# PIC16F1768 register map
Vendor: Microchip
Registers are 8-bit, read-write, reset 0x0 unless marked. A register's access mark holds for its fields unless they carry their own. Addresses are absolute, and some are shared; only a register's first bit layout is shown; [hi:lo] are bit positions; {n}, {i} and the like mark numbered series.

## SFR
0x00 INDF0 reset not defined — (power-on value xxxxxxxx)
0x01 INDF1 reset not defined — (power-on value xxxxxxxx)
0x02 PCL
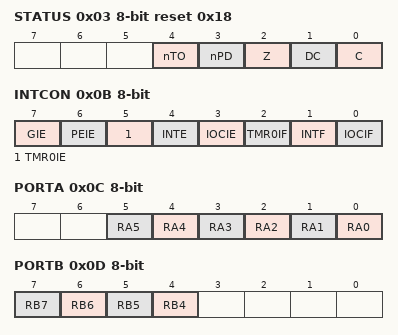
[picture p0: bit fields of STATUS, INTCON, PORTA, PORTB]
0x03 STATUS reset 0x18
  [4] nTO ro, [3] nPD ro, [2] Z, [1] DC, [0] C
0x04 FSR0L
0x05 FSR0H
0x06 FSR1L
0x07 FSR1H
0x08 BSR
  [4:0] BSR
0x09 WREG
  [7:0] WREG0
0x0A PCLATH
  [6:0] PCLATH
0x0B INTCON reset not defined — (power-on value 0000000x)
  [7] GIE, [6] PEIE, [5] TMR0IE, [4] INTE, [3] IOCIE, [2] TMR0IF, [1] INTF, [0] IOCIF ro
0x0C PORTA reset not defined — (power-on value --xxxxxx)
  [n] RA{n} (n=0..5)
0x0D PORTB reset not defined — (power-on value xxxx----)
  [n] RB{n} (n=4..7)
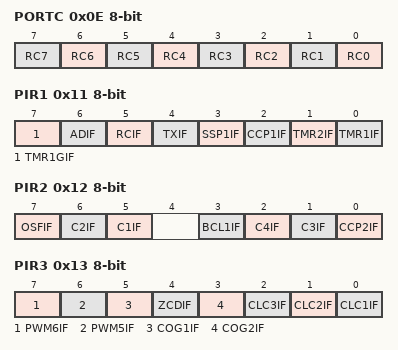
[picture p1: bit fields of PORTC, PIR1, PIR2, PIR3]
0x0E PORTC reset not defined — (power-on value xxxxxxxx)
  [n] RC{n} (n=0..7)
0x11 PIR1
  [7] TMR1GIF — Timer1 Gate Interrupt Flag bit
  [6] ADIF — A/D Converter Interrupt Flag bit
  [5] RCIF — EUSART Receive Interrupt Enable bit
  [4] TXIF — EUSART Transmit Interrupt Enable bit
  [3] SSP1IF — Synchronous Serial Port (MSSP) Interrupt Flag bit
  [2] CCP1IF
  [1] TMR2IF — TMR2 to PR2 Match Interrupt Flag bit
  [0] TMR1IF — TMR1 Overflow Interrupt Flag bit
0x12 PIR2
  [7] OSFIF — Oscillator Fail Interrupt Enable bit
  [6] C2IF — Numerically Controlled Oscillator Flag bit
  [5] C1IF — Numerically Controlled Oscillator Flag bit
  [3] BCL1IF — MSSP Bus Collision Interrupt Flag bit
  [2] C4IF — Numerically Controlled Oscillator Flag bit
  [1] C3IF
  [0] CCP2IF
0x13 PIR3
  [7] PWM6IF
  [6] PWM5IF
  [5] COG1IF
  [4] ZCDIF
  [3] COG2IF
  [2] CLC3IF — Configurable Logic Block Interrupt Flag
  [1] CLC2IF — Configurable Logic Block Interrupt Flag
  [0] CLC1IF — Configurable Logic Block Interrupt Flag
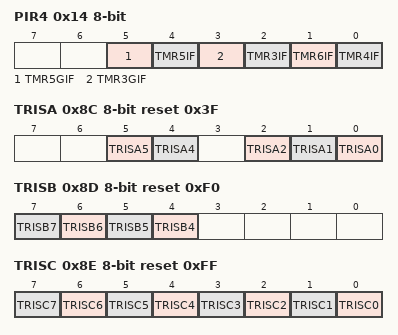
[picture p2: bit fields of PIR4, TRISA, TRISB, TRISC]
0x14 PIR4
  [5] TMR5GIF, [4] TMR5IF, [3] TMR3GIF, [2] TMR3IF, [1] TMR6IF, [0] TMR4IF
0x15 TMR0
0x8C TRISA reset 0x3F — PORTA Data Direction Control Register
  [5] TRISA5, [4] TRISA4, [2] TRISA2, [1] TRISA1, [0] TRISA0
0x8D TRISB reset 0xF0
  [n] TRISB{n} (n=4..7)
0x8E TRISC reset 0xFF — PORTC Data Direction Control Register
  [n] TRISC{n} (n=0..7)
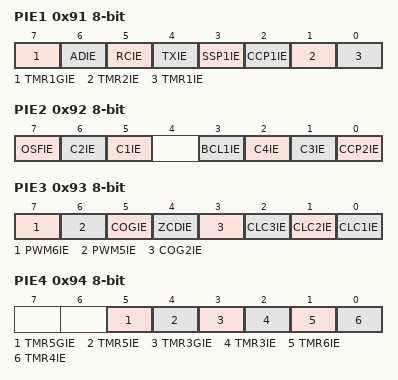
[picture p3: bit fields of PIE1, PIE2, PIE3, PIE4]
0x91 PIE1 — Peripheral Interrupt Enable Register 1
  [7] TMR1GIE — Timer1 Gate Interrupt Enable bit
  [6] ADIE — A/D Converter Interrupt Enable bit
  [5] RCIE
  [4] TXIE
  [3] SSP1IE
  [2] CCP1IE
  [1] TMR2IE — TMR2 to PR2 Match Interrupt Enable bit
  [0] TMR1IE — TMR1 Overflow Interrupt Enable bit
0x92 PIE2 — Peripheral Interrupt Enable Register 2
  [7] OSFIE, [6] C2IE, [5] C1IE, [3] BCL1IE, [2] C4IE, [1] C3IE, [0] CCP2IE
0x93 PIE3 — Peripheral Interrupt Enable Register 3
  [7] PWM6IE, [6] PWM5IE, [5] COGIE, [4] ZCDIE, [3] COG2IE, [2] CLC3IE, [1] CLC2IE, [0] CLC1IE
0x94 PIE4
  [5] TMR5GIE, [4] TMR5IE, [3] TMR3GIE, [2] TMR3IE, [1] TMR6IE, [0] TMR4IE
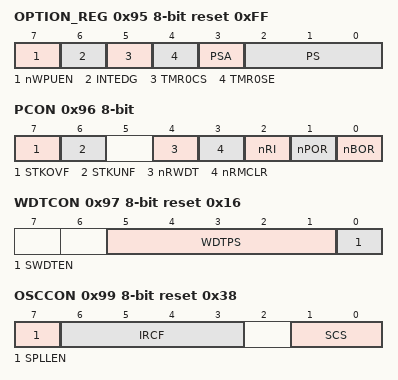
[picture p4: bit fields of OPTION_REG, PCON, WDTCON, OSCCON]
0x95 OPTION_REG reset 0xFF — Option Register
  [7] nWPUEN — Weak Pull-up Enable bit
  [6] INTEDG — Interrupt Edge Select bit
  [5] TMR0CS
  [4] TMR0SE — TMR0 Source Edge Select bit
  [3] PSA — Prescaler Active bit
  [2:0] PS
0x96 PCON reset not defined — Power Control Register (power-on value 00-111qq)
  [7] STKOVF — Stack Overflow Flag bit
  [6] STKUNF — Stack Underflow Flag bit
  [4] nRWDT
  [3] nRMCLR — MCLR Reset Flag bit
  [2] nRI — RESET Instruction Flag bit
  [1] nPOR — Power-on Reset Status bit
  [0] nBOR — Brown-out Reset Status bit
0x97 WDTCON reset 0x16 — Watchdog Timer Control Register
  [5:1] WDTPS
  [0] SWDTEN — Software Enable/Disable for Watch Dog Timer bit
0x98 OSCTUNE
  [5:0] TUN
0x99 OSCCON reset 0x38 — Oscillator Control Register
  [7] SPLLEN, [6:3] IRCF, [1:0] SCS
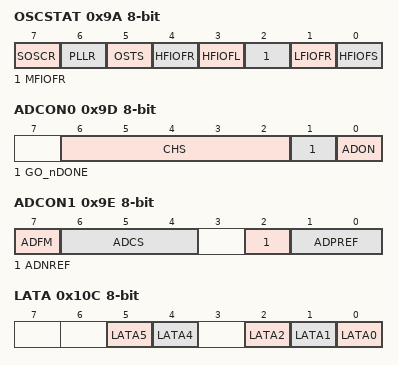
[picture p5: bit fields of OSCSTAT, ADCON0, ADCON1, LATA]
0x9A OSCSTAT ro reset not defined — Oscillator Status Register (power-on value 0qq00q0q)
  [7] SOSCR
  [6] PLLR
  [5] OSTS — Oscillator Start-up Time-out Status bit
  [4] HFIOFR
  [3] HFIOFL
  [2] MFIOFR
  [1] LFIOFR — Low Freqency Internal Oscillator Ready bit
  [0] HFIOFS — Low Freqency Internal Oscillator Ready bit
0x9B ADRESL reset not defined — A/D Result Register LSB (power-on value xxxxxxxx)
0x9C ADRESH reset not defined — A/D Result Register MSB (power-on value xxxxxxxx)
0x9D ADCON0 — Analog-to-Digital Control Register 0
  [6:2] CHS
  [1] GO_nDONE — A/D Conversion Status bit
  [0] ADON — A/D Module Enable bit
0x9E ADCON1 — Analog-to-Digital Control Register 1
  [7] ADFM — A/D Result Format Select bit
  [6:4] ADCS
  [2] ADNREF
  [1:0] ADPREF
0x9F ADCON2 — Analog-to-Digital Control Register 2
  [7:3] TRIGSEL
0x10C LATA reset not defined — (power-on value --xx-xxx)
  [5] LATA5, [4] LATA4, [2] LATA2, [1] LATA1, [0] LATA0
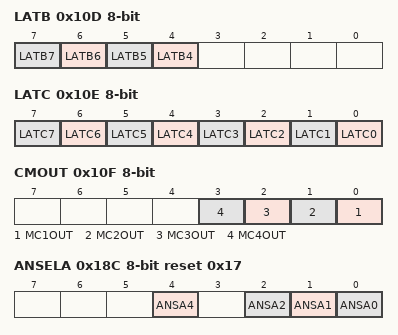
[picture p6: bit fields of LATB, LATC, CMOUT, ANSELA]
0x10D LATB reset not defined — (power-on value xxxx----)
  [n] LATB{n} (n=4..7)
0x10E LATC reset not defined — (power-on value xxxxxxxx)
  [n] LATC{n} (n=0..7)
0x10F CMOUT ro
  [n-1] MC{n}OUT (n=1..4)
0x18C ANSELA reset 0x17
  [4] ANSA4, [2] ANSA2, [1] ANSA1, [0] ANSA0
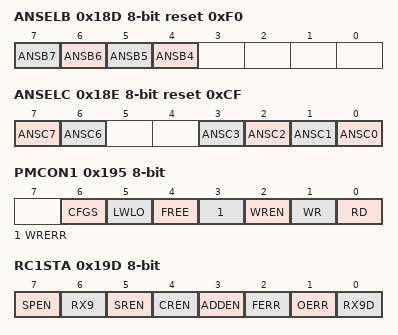
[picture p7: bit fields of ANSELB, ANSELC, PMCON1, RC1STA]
0x18D ANSELB reset 0xF0
  [n] ANSB{n} (n=4..7)
0x18E ANSELC reset 0xCF
  [7] ANSC7, [6] ANSC6, [n] ANSC{n} (n=0..3)
0x191 PMADRL
0x192 PMADRH reset 0x80
  [6:0] PMADRH
0x193 PMDATL reset not defined — (power-on value xxxxxxxx)
0x194 PMDATH reset not defined — (power-on value --xxxxxx)
  [5:0] PMDATH
0x195 PMCON1 reset not defined — (power-on value 1000x000)
  [6] CFGS — FLASH Program / Data EEPROM or Configuration Select bit
  [5] LWLO — Load Write Latches Only bit
  [4] FREE — Program FLASH Erase Enable bit
  [3] WRERR — Sequence Error Flag bit
  [2] WREN — Program/Erase Enable bit
  [1] WR — Write Control bit (can only be set)
  [0] RD — Read Control bit (can only be set)
0x196 PMCON2 wo
0x197 VREGCON reset 0x1
  [1] VREGPM
0x199 RC1REG ro
0x19A TX1REG
0x19B SP1BRGL
0x19C SP1BRGH
0x19D RC1STA
  [7] SPEN, [6] RX9, [5] SREN, [4] CREN, [3] ADDEN, [2] FERR ro, [1] OERR ro, [0] RX9D ro
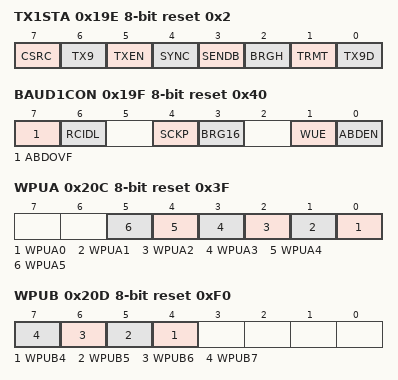
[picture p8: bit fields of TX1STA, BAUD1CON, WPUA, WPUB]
0x19E TX1STA reset 0x2
  [7] CSRC, [6] TX9, [5] TXEN, [4] SYNC, [3] SENDB, [2] BRGH, [1] TRMT ro, [0] TX9D
0x19F BAUD1CON reset 0x40
  [7] ABDOVF ro, [6] RCIDL ro, [4] SCKP, [3] BRG16, [1] WUE, [0] ABDEN
0x20C WPUA reset 0x3F
  [n] WPUA{n} (n=0..5)
0x20D WPUB reset 0xF0
  [n] WPUB{n} (n=4..7)
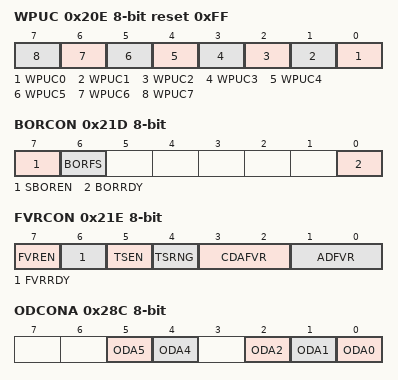
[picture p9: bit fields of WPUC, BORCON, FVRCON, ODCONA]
0x20E WPUC reset 0xFF
  [n] WPUC{n} (n=0..7)
0x21D BORCON reset not defined — (power-on value 10-----q)
  [7] SBOREN, [6] BORFS, [0] BORRDY ro
0x21E FVRCON reset not defined — (power-on value 0q000000)
  [7] FVREN, [6] FVRRDY ro, [5] TSEN, [4] TSRNG, [3:2] CDAFVR, [1:0] ADFVR
0x28C ODCONA
  [5] ODA5, [4] ODA4, [2] ODA2, [1] ODA1, [0] ODA0
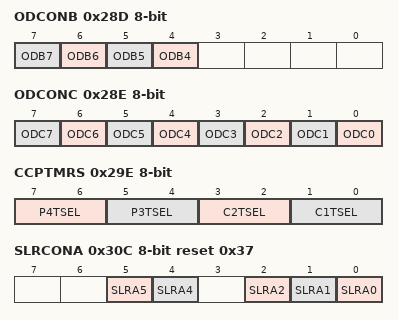
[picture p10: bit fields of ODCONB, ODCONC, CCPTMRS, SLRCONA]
0x28D ODCONB
  [n] ODB{n} (n=4..7)
0x28E ODCONC
  [n] ODC{n} (n=0..7)
0x29E CCPTMRS
  [7:6] P4TSEL, [5:4] P3TSEL, [3:2] C2TSEL, [1:0] C1TSEL
0x30C SLRCONA reset 0x37
  [5] SLRA5, [4] SLRA4, [2] SLRA2, [1] SLRA1, [0] SLRA0
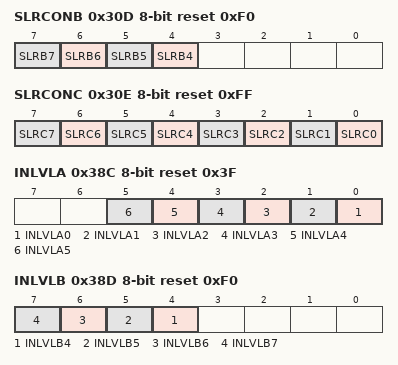
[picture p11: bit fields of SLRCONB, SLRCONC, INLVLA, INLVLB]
0x30D SLRCONB reset 0xF0
  [n] SLRB{n} (n=4..7)
0x30E SLRCONC reset 0xFF
  [n] SLRC{n} (n=0..7)
0x38C INLVLA reset 0x3F
  [n] INLVLA{n} (n=0..5)
0x38D INLVLB reset 0xF0
  [n] INLVLB{n} (n=4..7)
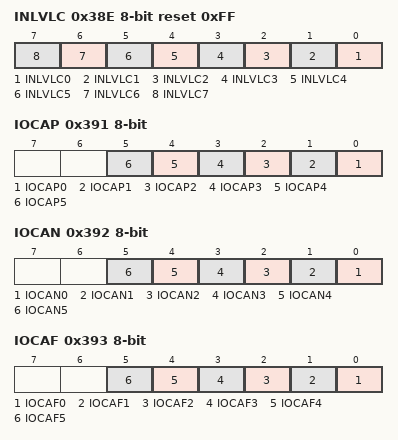
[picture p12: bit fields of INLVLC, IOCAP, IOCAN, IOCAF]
0x38E INLVLC reset 0xFF
  [n] INLVLC{n} (n=0..7)
0x391 IOCAP
  [n] IOCAP{n} (n=0..5)
0x392 IOCAN
  [n] IOCAN{n} (n=0..5)
0x393 IOCAF
  [n] IOCAF{n} (n=0..5)
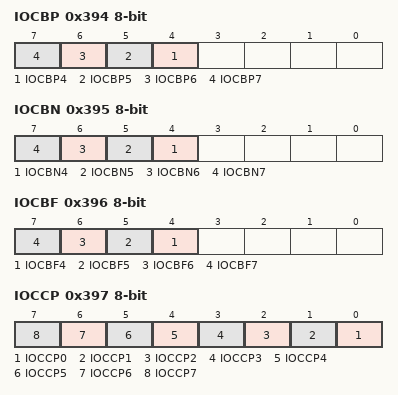
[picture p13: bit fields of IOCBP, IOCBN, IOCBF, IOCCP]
0x394 IOCBP
  [n] IOCBP{n} (n=4..7)
0x395 IOCBN
  [n] IOCBN{n} (n=4..7)
0x396 IOCBF
  [n] IOCBF{n} (n=4..7)
0x397 IOCCP
  [n] IOCCP{n} (n=0..7)
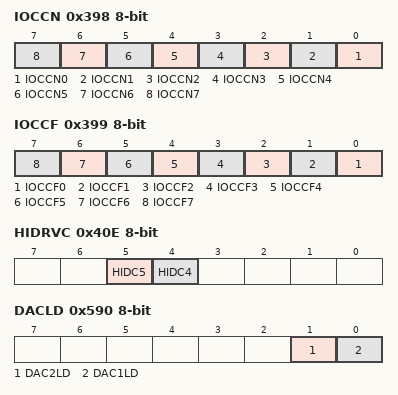
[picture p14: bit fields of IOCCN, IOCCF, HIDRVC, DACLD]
0x398 IOCCN
  [n] IOCCN{n} (n=0..7)
0x399 IOCCF
  [n] IOCCF{n} (n=0..7)
0x40E HIDRVC
  [5] HIDC5, [4] HIDC4
0x590 DACLD
  [1] DAC2LD, [0] DAC1LD
0xD8E PWMEN
  [5] MPWM6EN, [4] MPWM5EN
0xD8F PWMLD
  [5] MPWM6LD, [4] MPWM5LD
0xD90 PWMOUT
  [5] MPWM6OUT, [4] MPWM5OUT
0xE0F PPSLOCK
  [0] PPSLOCKED
0xE10 INTPPS reset 0x2
  [4:0] INTPPS
0xE11 T0CKIPPS reset 0x2
  [4:0] T0CKIPPS
0xE12 T1CKIPPS reset 0x5
  [4:0] T1CKIPPS
0xE13 T1GPPS reset 0x4
  [4:0] T1GPPS
0xE14 CCP1PPS reset 0x15
  [4:0] CCP1PPS
0xE15 CCP2PPS reset 0x13
  [4:0] CCP2PPS
0xE16 COG1INPPS reset 0x2
  [4:0] COG1INPPS
0xE17 COG2INPPS reset 0x2
  [4:0] COG2INPPS
0xE19 T2INPPS reset 0x5
  [4:0] T2INPPS
0xE1A T3CKIPPS reset 0x15
  [4:0] T3CKIPPS
0xE1B T3GPPS reset 0x14
  [4:0] T3GPPS
0xE1C T4INPPS reset 0x11
  [4:0] T4INPPS
0xE1D T5CKIPPS reset 0x10
  [4:0] T5CKIPPS
0xE1E T5GPPS reset 0x13
  [4:0] T5GPPS
0xE1F T6INPPS reset 0x3
  [4:0] T6INPPS
0xE20 SSPCLKPPS reset 0xE
  [4:0] SSPCLKPPS
0xE21 SSPDATPPS reset 0xC
  [4:0] SSPDATPPS
0xE22 SSPSSPPS reset 0x16
  [4:0] SSPSSPPS
0xE24 RXPPS reset 0xD
  [4:0] RXPPS
0xE25 CKPPS reset 0xF
  [4:0] CKPPS
0xE28 CLCIN0PPS reset 0x13
  [4:0] CLCIN0PPS
0xE29 CLCIN1PPS reset 0x14
  [4:0] CLCIN1PPS
0xE2A CLCIN2PPS reset 0x11
  [4:0] CLCIN2PPS
0xE2B CLCIN3PPS reset 0x5
  [4:0] CLCIN3PPS
0xE2C PRG1RPPS reset 0x14
  [4:0] PRG1RPPS
0xE2D PRG1FPPS reset 0x15
  [4:0] PRG1FPPS
0xE2E PRG2RPPS reset 0x14
  [4:0] PRG2RPPS
0xE2F PRG2FPPS reset 0x15
  [4:0] PRG2FPPS
0xE30 MD1CHPPS reset 0x3
  [4:0] MD1CHPPS
0xE31 MD1CLPPS reset 0x4
  [4:0] MD1CLPPS
0xE32 MD1MODPPS reset 0x5
  [4:0] MD1MODPPS
0xE33 MD2CHPPS reset 0x3
  [4:0] MD2CHPPS
0xE34 MD2CLPPS reset 0x4
  [4:0] MD2CLPPS
0xE35 MD2MODPPS reset 0x5
  [4:0] MD2MODPPS
{0xE90+i} RA{i}PPS (i=0..2)
  [4:0] RA{i}PPS
0xE94 RA4PPS
  [4:0] RA4PPS
0xE95 RA5PPS
  [4:0] RA5PPS
{0xE98+i} RB{i}PPS (i=4..7)
  [4:0] RB{i}PPS
{0xEA0+i} RC{i}PPS (i=0..7)
  [4:0] RC{i}PPS
0xF0F CLCDATA ro
  [2] MCLC3OUT, [1] MCLC2OUT, [0] MCLC1OUT
0xFE4 STATUS_SHAD reset not defined — (power-on value -----xxx)
  [2] Z_SHAD, [1] DC_SHAD, [0] C_SHAD
0xFE5 WREG_SHAD reset not defined — (power-on value xxxxxxxx)
0xFE6 BSR_SHAD reset not defined — (power-on value ---xxxxx)
  [4:0] BSR_SHAD
0xFE7 PCLATH_SHAD reset not defined — (power-on value -xxxxxxx)
  [6:0] PCLATH_SHAD
0xFE8 FSR0L_SHAD reset not defined — (power-on value xxxxxxxx)
0xFE9 FSR0H_SHAD reset not defined — (power-on value xxxxxxxx)
0xFEA FSR1L_SHAD reset not defined — (power-on value xxxxxxxx)
0xFEB FSR1H_SHAD reset not defined — (power-on value xxxxxxxx)
0xFED STKPTR reset 0x1F
  [4:0] STKPTR
0xFEE TOSL reset not defined — (power-on value xxxxxxxx)
0xFEF TOSH reset not defined — (power-on value -xxxxxxx)
  [6:0] TOSH
